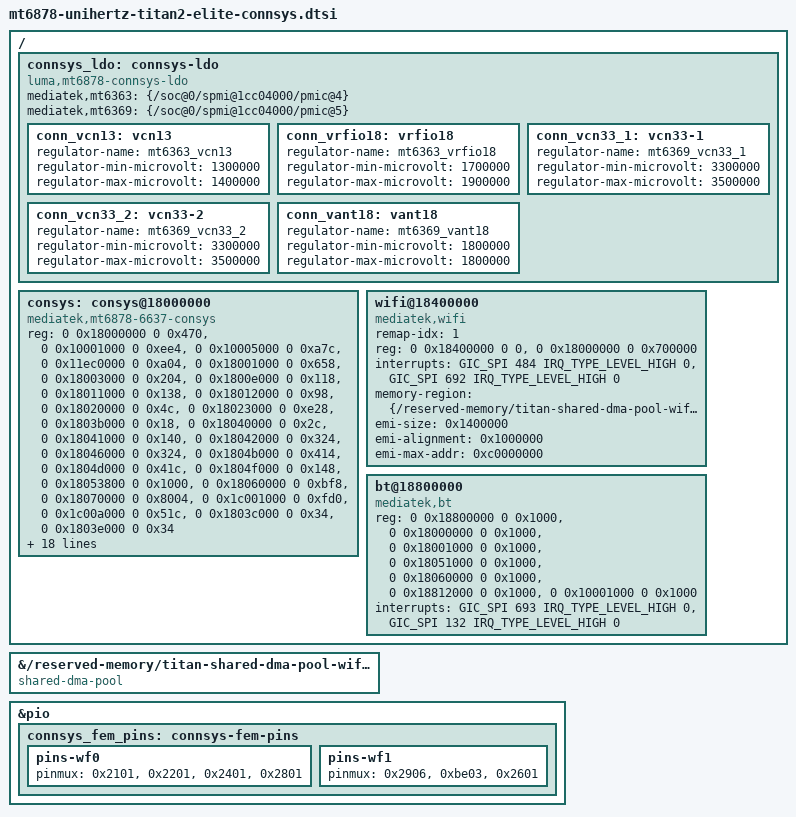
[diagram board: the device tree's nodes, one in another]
// SPDX-License-Identifier: (GPL-2.0 OR MIT)
/*
 * Titan 2 Elite connectivity subsystem (CONNSYS: Wi-Fi, Bluetooth) for the
 * out-of-tree MediaTek conninfra / gen4m / BT drivers.
 *
 * LK loads the connsys_bt/gnss/wifi images (MT6637 A-die variants) into its
 * consys EMI carve-out on every boot and programs the EMI MPU; its log shows
 * overall_pa=0x87e00000, gps 0x88a00000, wfdma 0x88b00000, scp-shm 0x89f00000.
 */

&{/reserved-memory/titan-shared-dma-pool-wifi-reserve-memory-dma@88b00000} {
	compatible = "shared-dma-pool";
};

&pio {
	connsys_fem_pins: connsys-fem-pins {
		/* wlan7207h (2.4 GHz) and wlan7207c (5 GHz) front-end control */
		/* GPIO37, 39, 189, 191 and 192 are camera power GPIOs on this board. */
		/* GPIO35 is NFC VEN and must stay a GPIO for native SIM access. */
		pins-wf0 {
			pinmux = <0x2101>, <0x2201>, <0x2401>, <0x2801>;
		};
		/* GPIO42/43 stay off this list: stock leaves them in GPIO mode
		 * with Wi-Fi on, and they are the speaker amp I2S4 BCK/LRCK. */
		pins-wf1 {
			pinmux = <0x2906>, <0xbe03>, <0x2601>;
		};
	};
};

/ {
	connsys_ldo: connsys-ldo {
		compatible = "luma,mt6878-connsys-ldo";
		mediatek,mt6363 = <&{/soc@0/spmi@1cc04000/pmic@4}>;
		mediatek,mt6369 = <&{/soc@0/spmi@1cc04000/pmic@5}>;

		conn_vcn13: vcn13 {
			regulator-name = "mt6363_vcn13";
			regulator-min-microvolt = <1300000>;
			regulator-max-microvolt = <1400000>;
		};

		conn_vrfio18: vrfio18 {
			regulator-name = "mt6363_vrfio18";
			regulator-min-microvolt = <1700000>;
			regulator-max-microvolt = <1900000>;
		};

		conn_vcn33_1: vcn33-1 {
			regulator-name = "mt6369_vcn33_1";
			regulator-min-microvolt = <3300000>;
			regulator-max-microvolt = <3500000>;
		};

		conn_vcn33_2: vcn33-2 {
			regulator-name = "mt6369_vcn33_2";
			regulator-min-microvolt = <3300000>;
			regulator-max-microvolt = <3500000>;
		};

		conn_vant18: vant18 {
			regulator-name = "mt6369_vant18";
			regulator-min-microvolt = <1800000>;
			regulator-max-microvolt = <1800000>;
		};
	};

	consys: consys@18000000 {
		compatible = "mediatek,mt6878-6637-consys";
		reg = <0 0x18000000 0 0x470>, <0 0x10001000 0 0xee4>,
		      <0 0x10005000 0 0xa7c>, <0 0x11ec0000 0 0xa04>,
		      <0 0x18001000 0 0x658>, <0 0x18003000 0 0x204>,
		      <0 0x1800e000 0 0x118>, <0 0x18011000 0 0x138>,
		      <0 0x18012000 0 0x98>, <0 0x18020000 0 0x4c>,
		      <0 0x18023000 0 0xe28>, <0 0x1803b000 0 0x18>,
		      <0 0x18040000 0 0x2c>, <0 0x18041000 0 0x140>,
		      <0 0x18042000 0 0x324>, <0 0x18046000 0 0x324>,
		      <0 0x1804b000 0 0x414>, <0 0x1804d000 0 0x41c>,
		      <0 0x1804f000 0 0x148>, <0 0x18053800 0 0x1000>,
		      <0 0x18060000 0 0xbf8>, <0 0x18070000 0 0x8004>,
		      <0 0x1c001000 0 0xfd0>, <0 0x1c00a000 0 0x51c>,
		      <0 0x1803c000 0 0x34>, <0 0x1803e000 0 0x34>;
		emi-addr = /bits/ 64 <0x87e00000>;
		emi-size = <0xc00000>;
		ro-bt-emi-size = <0x2e0000>;
		ro-gps-emi-size = <0xa0000>;
		ro-wifi-emi-size = <0x300000>;
		ro-emi-size = <0x680000>;
		rw-emi-size = <0x480000>;
		emi-alignment = <0x100000>;
		emi-max-addr = <0x90000000>;
		radio-support = "bt", "wifi";
		/* PMIC regmaps for the connsys LDO mode/RC-control registers */
		mediatek,mt6363 = <&{/soc@0/spmi@1cc04000/pmic@4}>;
		mediatek,mt6369 = <&{/soc@0/spmi@1cc04000/pmic@5}>;
		pinctrl-names = "default";
		pinctrl-0 = <&connsys_fem_pins>;
		mt6363_vcn13-supply = <&conn_vcn13>;
		mt6363_vrfio18-supply = <&conn_vrfio18>;
		mt6369_vcn33_1-supply = <&conn_vcn33_1>;
		mt6369_vcn33_2-supply = <&conn_vcn33_2>;
		mt6369_vant18-supply = <&conn_vant18>;
	};

	wifi@18400000 {
		compatible = "mediatek,wifi";
		remap-idx = <1>;
		reg = <0 0x18400000 0 0>, <0 0x18000000 0 0x700000>;
		interrupts = <GIC_SPI 484 IRQ_TYPE_LEVEL_HIGH 0>,
			     <GIC_SPI 692 IRQ_TYPE_LEVEL_HIGH 0>;
		memory-region = <&{/reserved-memory/titan-shared-dma-pool-wifi-reserve-memory-dma@88b00000}>;
		emi-size = <0x1400000>;
		emi-alignment = <0x1000000>;
		emi-max-addr = <0xc0000000>;
	};

	bt@18800000 {
		compatible = "mediatek,bt";
		reg = <0 0x18800000 0 0x1000>, <0 0x18000000 0 0x1000>,
		      <0 0x18001000 0 0x1000>, <0 0x18051000 0 0x1000>,
		      <0 0x18060000 0 0x1000>, <0 0x18812000 0 0x1000>,
		      <0 0x10001000 0 0x1000>;
		interrupts = <GIC_SPI 693 IRQ_TYPE_LEVEL_HIGH 0>,
			     <GIC_SPI 132 IRQ_TYPE_LEVEL_HIGH 0>;
	};
};
